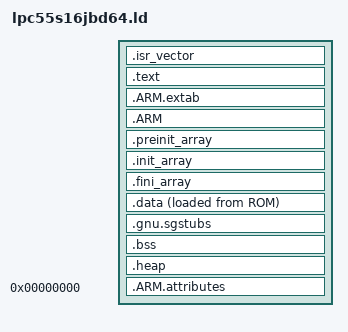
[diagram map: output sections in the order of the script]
/*
 * Linker script for LPC55S16JBD64 (LPC55S16), Cortex-M33 with TrustZone-M.
 *
 * Generated by scripts/nxp_trustzone.py from NXP MCUXpresso SDK data
 * (nxp-mcuxpresso/mcux-devices-lpc @ 977ea4da4f39):
 *   flash 0x3d000 bytes at 0x00000000 (secure alias 0x10000000)
 *   SRAM  0x10000 bytes at 0x20000000 (secure alias 0x30000000), SRAM
 */

ENTRY(Reset_Handler)

HEAP_SIZE  = DEFINED(__heap_size__)  ? __heap_size__  : 0x0400;
STACK_SIZE = DEFINED(__stack_size__) ? __stack_size__ : 0x0800;

/* Memories definition
 * TrustZone (NECTO): the MEMORY block comes from memory_map.ld, which NECTO
 * generates per target (FileLinker/secure, FileLinker/nonsecure) from the
 * TrustZone partition. It defines ROM, ROM_NSC and RAM; ROM_NSC is empty in
 * the Non-secure image.
 */
INCLUDE memory_map.ld

SECTIONS
{
  .isr_vector :
  {
    . = ALIGN(4);
    KEEP(*(.isr_vector))
    . = ALIGN(4);
  } >ROM

  .text :
  {
    . = ALIGN(4);
    *(.text)
    *(.text*)
    *(.rodata)
    *(.rodata*)
    *(.glue_7)
    *(.glue_7t)
    *(.eh_frame)
    KEEP(*(.init))
    KEEP(*(.fini))
    . = ALIGN(4);
  } >ROM

  .ARM.extab :
  {
    *(.ARM.extab* .gnu.linkonce.armextab.*)
  } >ROM

  .ARM :
  {
    __exidx_start = .;
    *(.ARM.exidx*)
    __exidx_end = .;
  } >ROM

  .preinit_array :
  {
    PROVIDE_HIDDEN(__preinit_array_start = .);
    KEEP(*(.preinit_array*))
    PROVIDE_HIDDEN(__preinit_array_end = .);
  } >ROM

  .init_array :
  {
    PROVIDE_HIDDEN(__init_array_start = .);
    KEEP(*(SORT(.init_array.*)))
    KEEP(*(.init_array*))
    PROVIDE_HIDDEN(__init_array_end = .);
  } >ROM

  .fini_array :
  {
    PROVIDE_HIDDEN(__fini_array_start = .);
    KEEP(*(SORT(.fini_array.*)))
    KEEP(*(.fini_array*))
    PROVIDE_HIDDEN(__fini_array_end = .);
  } >ROM

  .data :
  {
    . = ALIGN(4);
    __data_start__ = .;
    _sdata = .;
    *(.ramfunc*)
    *(.RamFunc*)
    *(.data)
    *(.data*)
    KEEP(*(.jcr*))
    . = ALIGN(4);
    __data_end__ = .;
    _edata = .;
  } >RAM AT> ROM

  /* Load address of .data, used by the startup to initialize it */
  __etext = LOADADDR(.data);
  _sidata = __etext;

  /* TrustZone: Secure Gateway veneers (-mcmse --cmse-implib) in the
     Non-secure Callable region. Empty in the Non-secure image.
     ld.lld needs the explicit address; GNU ld needs the dot assignment,
     otherwise the section has no contents when the veneers are sized and
     fails with "no address assigned to the veneers output section". */
  .gnu.sgstubs ORIGIN(ROM_NSC) :
  {
    . = ALIGN(32);
    *(.gnu.sgstubs*)
  } >ROM_NSC

  .bss (NOLOAD) :
  {
    . = ALIGN(4);
    __bss_start__ = .;
    _sbss = .;
    *(.bss)
    *(.bss*)
    *(COMMON)
    . = ALIGN(4);
    __bss_end__ = .;
    _ebss = .;
  } >RAM

  .heap (NOLOAD) :
  {
    . = ALIGN(8);
    __end__ = .;
    PROVIDE(end = .);
    PROVIDE(_end = .);
    __HeapBase = .;
    . += HEAP_SIZE;
    __HeapLimit = .;
    __heap_limit = .;
  } >RAM

  /* Stack at the top of RAM */
  __StackTop   = ORIGIN(RAM) + LENGTH(RAM);
  __StackLimit = __StackTop - STACK_SIZE;
  _estack      = __StackTop;
  PROVIDE(__stack = __StackTop);

  ASSERT(__StackLimit >= __HeapLimit, "region RAM overflowed with stack and heap")

  .ARM.attributes 0 : { *(.ARM.attributes) }
}
